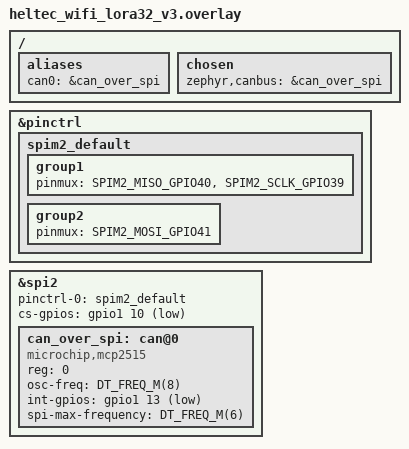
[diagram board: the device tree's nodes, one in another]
/*
 * Copyright (c) 2025 Nate Aquino
 *
 * SPDX-License-Identifier: Apache-2.0
 */


/ {
    aliases {
        can0 = &can_over_spi;
    };

    chosen {
        // esp32s3fn8 TWAI does not support CAN FD
        // use a spi controller instead, ovewrite chosen
        zephyr,canbus = &can_over_spi;
    };

};

&pinctrl {
    spim2_default: spim2_default {
		group1 {
			pinmux = <SPIM2_MISO_GPIO40>,
					<SPIM2_SCLK_GPIO39>;
		};

		group2 {
			pinmux = <SPIM2_MOSI_GPIO41>;
		};
	};
};


&spi2 {
	#address-cells = <1>;
	#size-cells = <0>;
    status = "okay";
    pinctrl-names = "default";
    pinctrl-0 = <&spim2_default>;
    cs-gpios = <&gpio1 10 GPIO_ACTIVE_LOW>; // GPIO0 42 == GPIO1 10

    can_over_spi: can@0 {
        status = "okay";
        reg = <0>; 
        compatible = "microchip,mcp2515";
        osc-freq = <DT_FREQ_M(8)>; 
        int-gpios = <&gpio1 13 GPIO_ACTIVE_LOW>; // GPIO0 45 == GPIO1 13
        spi-max-frequency = <DT_FREQ_M(6)>; // might be something else idk
    };
};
